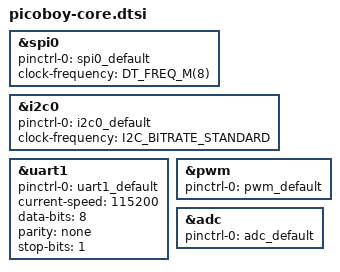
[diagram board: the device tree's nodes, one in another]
/*
 * Copyright (c) 2023-2025 TiaC Systems
 * SPDX-License-Identifier: Apache-2.0
 */

#include <freq.h>
#include <zephyr/dt-bindings/i2c/i2c.h>

&spi0 {
	pinctrl-0 = <&spi0_default>;
	pinctrl-names = "default";
	clock-frequency = <DT_FREQ_M(8)>;
};

&i2c0 {
	pinctrl-0 = <&i2c0_default>;
	pinctrl-names = "default";
	clock-frequency = <I2C_BITRATE_STANDARD>;
};

&uart1 {
	pinctrl-0 = <&uart1_default>;
	pinctrl-names = "default";
	current-speed = <115200>;
	data-bits = <8>;
	parity = "none";
	stop-bits = "1";
};

&pwm {
	pinctrl-0 = <&pwm_default>;
	pinctrl-names = "default";
};

&adc {
	pinctrl-0 = <&adc_default>;
	pinctrl-names = "default";
};
